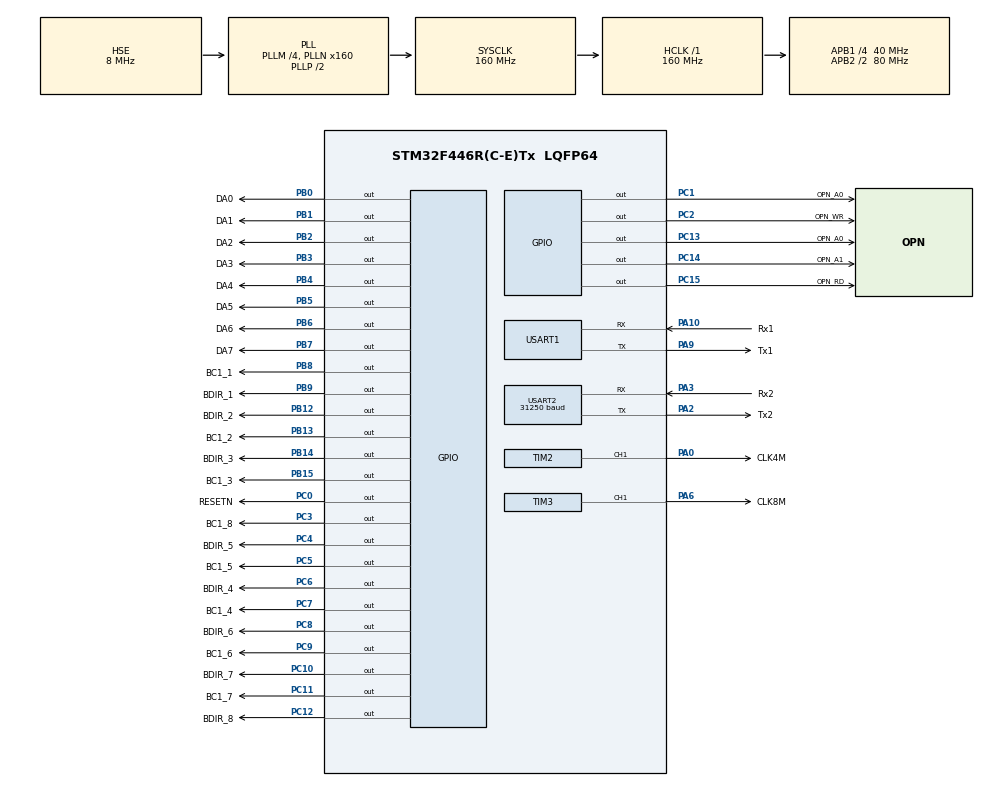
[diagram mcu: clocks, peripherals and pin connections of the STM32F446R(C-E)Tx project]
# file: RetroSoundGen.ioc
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Mcu.Family=STM32F4
Mcu.Name=STM32F446R(C-E)Tx
Mcu.Package=LQFP64
NVIC.PriorityGroup=NVIC_PRIORITYGROUP_4
NVIC.USART1_IRQn=true\:0\:0\:false\:false\:true\:true\:true\:true
NVIC.USART2_IRQn=true\:0\:0\:false\:false\:true\:true\:true\:true
PA0-WKUP.GPIO_Label=CLK4M
PA0-WKUP.Signal=S_TIM2_CH1_ETR
PA10.GPIO_Label=Rx1
PA10.Mode=Asynchronous
PA10.Signal=USART1_RX
PA13.Mode=Serial_Wire
PA13.Signal=SYS_JTMS-SWDIO
PA14.Mode=Serial_Wire
PA14.Signal=SYS_JTCK-SWCLK
PA2.GPIO_Label=Tx2
PA2.Mode=Asynchronous
PA2.Signal=USART2_TX
PA3.GPIO_Label=Rx2
PA3.Mode=Asynchronous
PA3.Signal=USART2_RX
PA6.GPIO_Label=CLK8M
PA6.Signal=S_TIM3_CH1
PA9.GPIO_Label=Tx1
PA9.Mode=Asynchronous
PA9.Signal=USART1_TX
PB0.GPIO_Label=DA0
PB0.Signal=GPIO_Output
PB1.GPIO_Label=DA1
PB1.Signal=GPIO_Output
PB12.GPIO_Label=BDIR_2
PB12.GPIO_Speed=GPIO_SPEED_FREQ_VERY_HIGH
PB12.Signal=GPIO_Output
PB13.GPIO_Label=BC1_2
PB13.GPIO_Speed=GPIO_SPEED_FREQ_VERY_HIGH
PB13.Signal=GPIO_Output
PB14.GPIO_Label=BDIR_3
PB14.Signal=GPIO_Output
PB15.GPIO_Label=BC1_3
PB15.Signal=GPIO_Output
PB2.GPIO_Label=DA2
PB2.Signal=GPIO_Output
PB3.GPIO_Label=DA3
PB3.Signal=GPIO_Output
PB4.GPIO_Label=DA4
PB4.Signal=GPIO_Output
PB5.GPIO_Label=DA5
PB5.Signal=GPIO_Output
PB6.GPIO_Label=DA6
PB6.Signal=GPIO_Output
PB7.GPIO_Label=DA7
PB7.Signal=GPIO_Output
PB8.GPIO_Label=BC1_1
PB8.GPIO_Speed=GPIO_SPEED_FREQ_VERY_HIGH
PB8.Signal=GPIO_Output
PB9.GPIO_Label=BDIR_1
PB9.GPIO_Speed=GPIO_SPEED_FREQ_VERY_HIGH
PB9.Signal=GPIO_Output
PC0.GPIO_Label=RESETN
PC0.Signal=GPIO_Output
PC1.GPIO_Label=OPN_A0
PC1.Signal=GPIO_Output
PC10.GPIO_Label=BDIR_7
PC10.Signal=GPIO_Output
PC11.GPIO_Label=BC1_7
PC11.Signal=GPIO_Output
PC12.GPIO_Label=BDIR_8
PC12.Signal=GPIO_Output
PC13.GPIO_Label=OPN_A0
PC13.Signal=GPIO_Output
PC14-OSC32_IN.GPIO_Label=OPN_A1
PC14-OSC32_IN.Signal=GPIO_Output
PC15-OSC32_OUT.GPIO_Label=OPN_RD
PC15-OSC32_OUT.Signal=GPIO_Output
PC2.GPIO_Label=OPN_WR
PC2.PinState=GPIO_PIN_RESET
PC2.Signal=GPIO_Output
PC3.GPIO_Label=BC1_8
PC3.Signal=GPIO_Output
PC4.GPIO_Label=BDIR_5
PC4.Signal=GPIO_Output
PC5.GPIO_Label=BC1_5
PC5.Signal=GPIO_Output
PC6.GPIO_Label=BDIR_4
PC6.Signal=GPIO_Output
PC7.GPIO_Label=BC1_4
PC7.Signal=GPIO_Output
PC8.GPIO_Label=BDIR_6
PC8.Signal=GPIO_Output
PC9.GPIO_Label=BC1_6
PC9.Signal=GPIO_Output
PH0-OSC_IN.Mode=HSE-External-Oscillator
PH0-OSC_IN.Signal=RCC_OSC_IN
PH1-OSC_OUT.Mode=HSE-External-Oscillator
PH1-OSC_OUT.Signal=RCC_OSC_OUT
ProjectManager.HeapSize=0x200
ProjectManager.StackSize=0x400
ProjectManager.TargetToolchain=STM32CubeIDE
RCC.AHBFreq_Value=160000000
RCC.APB1CLKDivider=RCC_HCLK_DIV4
RCC.APB1Freq_Value=40000000
RCC.APB1TimFreq_Value=80000000
RCC.APB2CLKDivider=RCC_HCLK_DIV2
RCC.APB2Freq_Value=80000000
RCC.APB2TimFreq_Value=160000000
RCC.CortexFreq_Value=160000000
RCC.HCLKFreq_Value=160000000
RCC.HSE_VALUE=8000000
RCC.PLLM=4
RCC.PLLN=160
RCC.PLLQ=5
RCC.PLLSAIM=4
RCC.PLLSAIN=96
RCC.PLLSAIP=RCC_PLLSAIP_DIV4
RCC.PLLSourceVirtual=RCC_PLLSOURCE_HSE
RCC.RCC_MCO1Source=RCC_MCO1SOURCE_HSE
RCC.SYSCLKFreq_VALUE=160000000
RCC.SYSCLKSource=RCC_SYSCLKSOURCE_PLLCLK
RCC.USBCLockSelection=RCC_CLK48CLKSOURCE_PLLSAIP
RCC.USBFreq_Value=48000000
RCC.VCOOutputFreq_Value=320000000
SH.S_TIM2_CH1_ETR.0=TIM2_CH1,PWM Generation1 CH1
SH.S_TIM3_CH1.0=TIM3_CH1,PWM Generation1 CH1
TIM2.Channel-PWM\ Generation1\ CH1=TIM_CHANNEL_1
TIM2.Period=19
TIM2.Pulse-PWM\ Generation1\ CH1=10
TIM3.Channel-PWM\ Generation1\ CH1=TIM_CHANNEL_1
TIM3.Period=9
TIM3.Pulse-PWM\ Generation1\ CH1=5
USART1.VirtualMode=VM_ASYNC
USART2.BaudRate=31250
USART2.VirtualMode=VM_ASYNC
VP_TIM2_VS_ClockSourceINT.Mode=Internal
VP_TIM3_VS_ClockSourceINT.Mode=Internal
board=custom

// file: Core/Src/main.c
/* USER CODE BEGIN Header */
/**
  ******************************************************************************
  * @file           : main.c
  * @brief          : Main program body
  ******************************************************************************
  * @attention
  *
  * Copyright (c) 2024 STMicroelectronics.
  * All rights reserved.
  *
  * This software is licensed under terms that can be found in the LICENSE file
  * in the root directory of this software component.
  * If no LICENSE file comes with this software, it is provided AS-IS.
  *
  ******************************************************************************
  */
/* USER CODE END Header */
#include "main.h"

TIM_HandleTypeDef htim2;
TIM_HandleTypeDef htim3;

UART_HandleTypeDef huart1;
UART_HandleTypeDef huart2;

void SystemClock_Config(void);
static void MX_GPIO_Init(void);
static void MX_USART1_UART_Init(void);
static void MX_USART2_UART_Init(void);
static void MX_TIM3_Init(void);
static void MX_TIM2_Init(void);

/* USER CODE BEGIN 0 */
//uint32_t sysclk_freq, cpu_cycle_ns;

//#define NOTE_ON		(0x90)
//#define NOTE_OFF	(0x80)

//#define U_BUF_SIZE (64)
//#define MIDI_BUF_SIZE (64)
//static const uint8_t MCP4725_ADDR = 0x61 << 1; // Use 8-bit address

/* USER CODE END 0 */

int main(void)
{

  /* USER CODE BEGIN 1 */
  int cnt = 0;
  /* USER CODE END 1 */

  /* MCU Configuration--------------------------------------------------------*/

  /* Reset of all peripherals, Initializes the Flash interface and the Systick. */
  HAL_Init();

  /* Configure the system clock */
  SystemClock_Config();

  /* Initialize all configured peripherals */
  MX_GPIO_Init();
  MX_USART1_UART_Init();
  MX_USART2_UART_Init();
  MX_TIM3_Init();
  MX_TIM2_Init();
  /* USER CODE BEGIN 2 */
  HAL_UART_Receive_IT(&huart2, &rmidi_data, 1);

  if (HAL_TIM_PWM_Start(&htim2, TIM_CHANNEL_1) != HAL_OK) {
    Error_Handler();
  }
  if (HAL_TIM_PWM_Start(&htim3, TIM_CHANNEL_1) != HAL_OK) {
    Error_Handler();
  }
  uart_init();
  //HAL_TIM_Base_Start(&htim5);
  printf("RetroSoundGen start......\n");
  //sysclk_freq = HAL_RCC_GetSysClockFreq();
  //cpu_cycle_ns = 1000000000/sysclk_freq;
  reset_psg();
  init_psg();
  /* USER CODE END 2 */

  /* Infinite loop */
  /* USER CODE BEGIN WHILE */
  while (1)
  {
	uart_proc();
    /* USER CODE END WHILE */

    /* USER CODE BEGIN 3 */
    //if(u_kbhit()){
    //	cmd_loop();
    //}
    //cnt++;
    //if((cnt % 500000) == 0)
    //	u_putchar('a');
  }
  /* USER CODE END 3 */
}

void SystemClock_Config(void)
{
  RCC_OscInitTypeDef RCC_OscInitStruct = {0};
  RCC_ClkInitTypeDef RCC_ClkInitStruct = {0};

  /** Configure the main internal regulator output voltage
  */
  __HAL_RCC_PWR_CLK_ENABLE();
  __HAL_PWR_VOLTAGESCALING_CONFIG(PWR_REGULATOR_VOLTAGE_SCALE1);

  /** Initializes the RCC Oscillators according to the specified parameters
  * in the RCC_OscInitTypeDef structure.
  */
  RCC_OscInitStruct.OscillatorType = RCC_OSCILLATORTYPE_HSE;
  RCC_OscInitStruct.HSEState = RCC_HSE_ON;
  RCC_OscInitStruct.PLL.PLLState = RCC_PLL_ON;
  RCC_OscInitStruct.PLL.PLLSource = RCC_PLLSOURCE_HSE;
  RCC_OscInitStruct.PLL.PLLM = 4;
  RCC_OscInitStruct.PLL.PLLN = 160;
  RCC_OscInitStruct.PLL.PLLP = RCC_PLLP_DIV2;
  RCC_OscInitStruct.PLL.PLLQ = 5;
  RCC_OscInitStruct.PLL.PLLR = 2;
  if (HAL_RCC_OscConfig(&RCC_OscInitStruct) != HAL_OK)
  {
    Error_Handler();
  }

  /** Initializes the CPU, AHB and APB buses clocks
  */
  RCC_ClkInitStruct.ClockType = RCC_CLOCKTYPE_HCLK|RCC_CLOCKTYPE_SYSCLK
                              |RCC_CLOCKTYPE_PCLK1|RCC_CLOCKTYPE_PCLK2;
  RCC_ClkInitStruct.SYSCLKSource = RCC_SYSCLKSOURCE_PLLCLK;
  RCC_ClkInitStruct.AHBCLKDivider = RCC_SYSCLK_DIV1;
  RCC_ClkInitStruct.APB1CLKDivider = RCC_HCLK_DIV4;
  RCC_ClkInitStruct.APB2CLKDivider = RCC_HCLK_DIV2;

  if (HAL_RCC_ClockConfig(&RCC_ClkInitStruct, FLASH_LATENCY_5) != HAL_OK)
  {
    Error_Handler();
  }
}

static void MX_TIM2_Init(void)
{

  TIM_ClockConfigTypeDef sClockSourceConfig = {0};
  TIM_MasterConfigTypeDef sMasterConfig = {0};
  TIM_OC_InitTypeDef sConfigOC = {0};

  htim2.Instance = TIM2;
  htim2.Init.Prescaler = 0;
  htim2.Init.CounterMode = TIM_COUNTERMODE_UP;
  htim2.Init.Period = 19;
  htim2.Init.ClockDivision = TIM_CLOCKDIVISION_DIV1;
  htim2.Init.AutoReloadPreload = TIM_AUTORELOAD_PRELOAD_DISABLE;
  if (HAL_TIM_Base_Init(&htim2) != HAL_OK)
  {
    Error_Handler();
  }
  sClockSourceConfig.ClockSource = TIM_CLOCKSOURCE_INTERNAL;
  if (HAL_TIM_ConfigClockSource(&htim2, &sClockSourceConfig) != HAL_OK)
  {
    Error_Handler();
  }
  if (HAL_TIM_PWM_Init(&htim2) != HAL_OK)
  {
    Error_Handler();
  }
  sMasterConfig.MasterOutputTrigger = TIM_TRGO_RESET;
  sMasterConfig.MasterSlaveMode = TIM_MASTERSLAVEMODE_DISABLE;
  if (HAL_TIMEx_MasterConfigSynchronization(&htim2, &sMasterConfig) != HAL_OK)
  {
    Error_Handler();
  }
  sConfigOC.OCMode = TIM_OCMODE_PWM1;
  sConfigOC.Pulse = 10;
  sConfigOC.OCPolarity = TIM_OCPOLARITY_HIGH;
  sConfigOC.OCFastMode = TIM_OCFAST_DISABLE;
  if (HAL_TIM_PWM_ConfigChannel(&htim2, &sConfigOC, TIM_CHANNEL_1) != HAL_OK)
  {
    Error_Handler();
  }
  HAL_TIM_MspPostInit(&htim2);

}

static void MX_TIM3_Init(void)
{

  TIM_ClockConfigTypeDef sClockSourceConfig = {0};
  TIM_MasterConfigTypeDef sMasterConfig = {0};
  TIM_OC_InitTypeDef sConfigOC = {0};

  htim3.Instance = TIM3;
  htim3.Init.Prescaler = 0;
  htim3.Init.CounterMode = TIM_COUNTERMODE_UP;
  htim3.Init.Period = 9;
  htim3.Init.ClockDivision = TIM_CLOCKDIVISION_DIV1;
  htim3.Init.AutoReloadPreload = TIM_AUTORELOAD_PRELOAD_DISABLE;
  if (HAL_TIM_Base_Init(&htim3) != HAL_OK)
  {
    Error_Handler();
  }
  sClockSourceConfig.ClockSource = TIM_CLOCKSOURCE_INTERNAL;
  if (HAL_TIM_ConfigClockSource(&htim3, &sClockSourceConfig) != HAL_OK)
  {
    Error_Handler();
  }
  if (HAL_TIM_PWM_Init(&htim3) != HAL_OK)
  {
    Error_Handler();
  }
  sMasterConfig.MasterOutputTrigger = TIM_TRGO_RESET;
  sMasterConfig.MasterSlaveMode = TIM_MASTERSLAVEMODE_DISABLE;
  if (HAL_TIMEx_MasterConfigSynchronization(&htim3, &sMasterConfig) != HAL_OK)
  {
    Error_Handler();
  }
  sConfigOC.OCMode = TIM_OCMODE_PWM1;
  sConfigOC.Pulse = 5;
  sConfigOC.OCPolarity = TIM_OCPOLARITY_HIGH;
  sConfigOC.OCFastMode = TIM_OCFAST_DISABLE;
  if (HAL_TIM_PWM_ConfigChannel(&htim3, &sConfigOC, TIM_CHANNEL_1) != HAL_OK)
  {
    Error_Handler();
  }
  HAL_TIM_MspPostInit(&htim3);

}

static void MX_USART1_UART_Init(void)
{

  huart1.Instance = USART1;
  huart1.Init.BaudRate = 115200;
  huart1.Init.WordLength = UART_WORDLENGTH_8B;
  huart1.Init.StopBits = UART_STOPBITS_1;
  huart1.Init.Parity = UART_PARITY_NONE;
  huart1.Init.Mode = UART_MODE_TX_RX;
  huart1.Init.HwFlowCtl = UART_HWCONTROL_NONE;
  huart1.Init.OverSampling = UART_OVERSAMPLING_16;
  if (HAL_UART_Init(&huart1) != HAL_OK)
  {
    Error_Handler();
  }

}

static void MX_USART2_UART_Init(void)
{

  huart2.Instance = USART2;
  huart2.Init.BaudRate = 31250;
  huart2.Init.WordLength = UART_WORDLENGTH_8B;
  huart2.Init.StopBits = UART_STOPBITS_1;
  huart2.Init.Parity = UART_PARITY_NONE;
  huart2.Init.Mode = UART_MODE_TX_RX;
  huart2.Init.HwFlowCtl = UART_HWCONTROL_NONE;
  huart2.Init.OverSampling = UART_OVERSAMPLING_16;
  if (HAL_UART_Init(&huart2) != HAL_OK)
  {
    Error_Handler();
  }

}

static void MX_GPIO_Init(void)
{
  GPIO_InitTypeDef GPIO_InitStruct = {0};

  /* GPIO Ports Clock Enable */
  __HAL_RCC_GPIOC_CLK_ENABLE();
  __HAL_RCC_GPIOH_CLK_ENABLE();
  __HAL_RCC_GPIOA_CLK_ENABLE();
  __HAL_RCC_GPIOB_CLK_ENABLE();

  /*Configure GPIO pin Output Level */
  HAL_GPIO_WritePin(GPIOC, OPN_A0_Pin|OPN_A1_Pin|OPN_RD_Pin|RESETN_Pin
                          |OPN_A0C1_Pin|OPN_WR_Pin|BC1_8_Pin|BDIR_5_Pin
                          |BC1_5_Pin|BDIR_4_Pin|BC1_4_Pin|BDIR_6_Pin
                          |BC1_6_Pin|BDIR_7_Pin|BC1_7_Pin|BDIR_8_Pin, GPIO_PIN_RESET);

  /*Configure GPIO pin Output Level */
  HAL_GPIO_WritePin(GPIOB, DA0_Pin|DA1_Pin|DA2_Pin|BDIR_2_Pin
                          |BC1_2_Pin|BDIR_3_Pin|BC1_3_Pin|DA3_Pin
                          |DA4_Pin|DA5_Pin|DA6_Pin|DA7_Pin
                          |BC1_1_Pin|BDIR_1_Pin, GPIO_PIN_RESET);

  /*Configure GPIO pins : OPN_A0_Pin OPN_A1_Pin OPN_RD_Pin RESETN_Pin
                           OPN_A0C1_Pin OPN_WR_Pin BC1_8_Pin BDIR_5_Pin
                           BC1_5_Pin BDIR_4_Pin BC1_4_Pin BDIR_6_Pin
                           BC1_6_Pin BDIR_7_Pin BC1_7_Pin BDIR_8_Pin */
  GPIO_InitStruct.Pin = OPN_A0_Pin|OPN_A1_Pin|OPN_RD_Pin|RESETN_Pin
                          |OPN_A0C1_Pin|OPN_WR_Pin|BC1_8_Pin|BDIR_5_Pin
                          |BC1_5_Pin|BDIR_4_Pin|BC1_4_Pin|BDIR_6_Pin
                          |BC1_6_Pin|BDIR_7_Pin|BC1_7_Pin|BDIR_8_Pin;
  GPIO_InitStruct.Mode = GPIO_MODE_OUTPUT_PP;
  GPIO_InitStruct.Pull = GPIO_NOPULL;
  GPIO_InitStruct.Speed = GPIO_SPEED_FREQ_LOW;
  HAL_GPIO_Init(GPIOC, &GPIO_InitStruct);

  /*Configure GPIO pins : DA0_Pin DA1_Pin DA2_Pin BDIR_3_Pin
                           BC1_3_Pin DA3_Pin DA4_Pin DA5_Pin
                           DA6_Pin DA7_Pin */
  GPIO_InitStruct.Pin = DA0_Pin|DA1_Pin|DA2_Pin|BDIR_3_Pin
                          |BC1_3_Pin|DA3_Pin|DA4_Pin|DA5_Pin
                          |DA6_Pin|DA7_Pin;
  GPIO_InitStruct.Mode = GPIO_MODE_OUTPUT_PP;
  GPIO_InitStruct.Pull = GPIO_NOPULL;
  GPIO_InitStruct.Speed = GPIO_SPEED_FREQ_LOW;
  HAL_GPIO_Init(GPIOB, &GPIO_InitStruct);

  /*Configure GPIO pins : BDIR_2_Pin BC1_2_Pin BC1_1_Pin BDIR_1_Pin */
  GPIO_InitStruct.Pin = BDIR_2_Pin|BC1_2_Pin|BC1_1_Pin|BDIR_1_Pin;
  GPIO_InitStruct.Mode = GPIO_MODE_OUTPUT_PP;
  GPIO_InitStruct.Pull = GPIO_NOPULL;
  GPIO_InitStruct.Speed = GPIO_SPEED_FREQ_VERY_HIGH;
  HAL_GPIO_Init(GPIOB, &GPIO_InitStruct);

}

void Error_Handler(void)
{
  __disable_irq();
  while (1)
  {
  }
}
